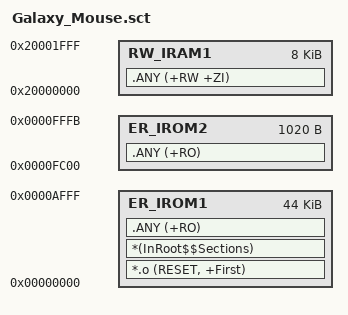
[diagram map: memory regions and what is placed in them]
; *************************************************************
; *** Scatter-Loading Description File generated by uVision ***
; *************************************************************

LR_IROM1 0x00000000 0x0000B000  {    ; load region size_region
  ER_IROM1 0x00000000 0x0000B000  {  ; load address = execution address
   *.o (RESET, +First)
   *(InRoot$$Sections)
   .ANY (+RO)
  }
  RW_IRAM1 0x20000000 0x00002000  {  ; RW data
   .ANY (+RW +ZI)
  }
}

LR_IROM2 0x0000FC00 0x000003FC  {
  ER_IROM2 0x0000FC00 0x000003FC  {  ; load address = execution address
   .ANY (+RO)
  }
}
